# IWRL6432 register map
File version: 1.0
CPU: CM4 1.0, other endian, MPU, FPU, 3 interrupt priority bits
Registers are 32-bit, read-write, reset 0x0 unless marked. A register's access mark holds for its fields unless they carry their own. Offsets are from the block's base; [hi:lo] are bit positions; {n}, {i} and the like mark numbered series; 'fields as' and 'values as' point back to an identical list.

## TPCC_B (part 1 of 2) — TPCC
Base 0x55080000
Same registers: TPCC_A 0x56000000
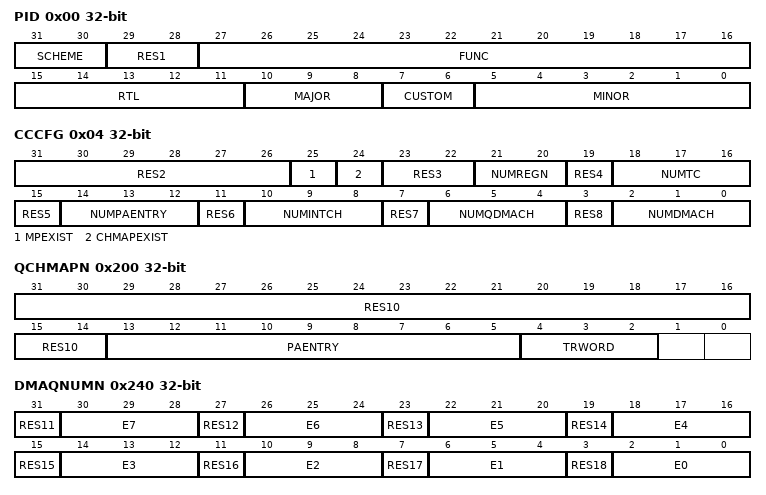
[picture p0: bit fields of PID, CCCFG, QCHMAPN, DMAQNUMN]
0x00 PID — Peripheral ID Register
  [31:30] SCHEME — [31:30] PID Scheme: Used to distinguish between old ID scheme and current. Spare bit to encode future schemes EDMA uses 'new scheme' indicated with value of 0x1.
  [29:28] RES1 — [29:28] RESERVE FIELD
  [27:16] FUNC — [27:16] Function indicates a software compatible module family.
  [15:11] RTL — [15:11] RTL Version
  [10:8] MAJOR — [10:8] Major Revision
  [7:6] CUSTOM — [7:6] Custom revision field: Not used on this version of EDMA.
  [5:0] MINOR — [5:0] Minor Revision
0x04 CCCFG — CC Configuration Register
  [31:26] RES2 — [31:26] RESERVE FIELD
  [25] MPEXIST — [25:25] Memory Protection Existence MPEXIST = 0 : No memory protection. MPEXIST = 1 : Memory Protection logic included.
  [24] CHMAPEXIST — [24:24] Channel Mapping Existence CHMAPEXIST = 0 : No Channel mapping. CHMAPEXIST = 1 : Channel mapping logic included.
  [23:22] RES3 — [23:22] RESERVE FIELD
  [21:20] NUMREGN — [21:20] Number of MP and Shadow regions
  [35-4n] RES{n} (n=4..8) — [{35-4n}:{35-4n}] RESERVE FIELD
  [18:16] NUMTC — [18:16] Number of Queues/Number of TCs
  [14:12] NUMPAENTRY — [14:12] Number of PaRAM entries
  [10:8] NUMINTCH — [10:8] Number of Interrupt Channels
  [6:4] NUMQDMACH — [6:4] Number of QDMA Channels
  [2:0] NUMDMACH — [2:0] Number of DMA Channels
0x200 QCHMAPN — QDMA Channel N Mapping Register
  [31:14] RES10 — [31:14] RESERVE FIELD
  [13:5] PAENTRY — [13:5] PaRAM Entry number for QDMA Channel N.
  [4:2] TRWORD — [4:2] TRWORD points to the specific trigger word of the PaRAM Entry defined by PAENTRY. A write to the trigger word results in a QDMA Event being recognized.
0x240 DMAQNUMN — DMA Queue Number Register n Contains the Event queue number to be used for the corresponding DMA Channel.
  [75-4n] RES{n} (n=11..18) — [{75-4n}:{75-4n}] RESERVE FIELD
  [4n+2:4n] E{n} (n=0..7) — [{4n+2}:{4n}] DMA Queue Number for event #{n}
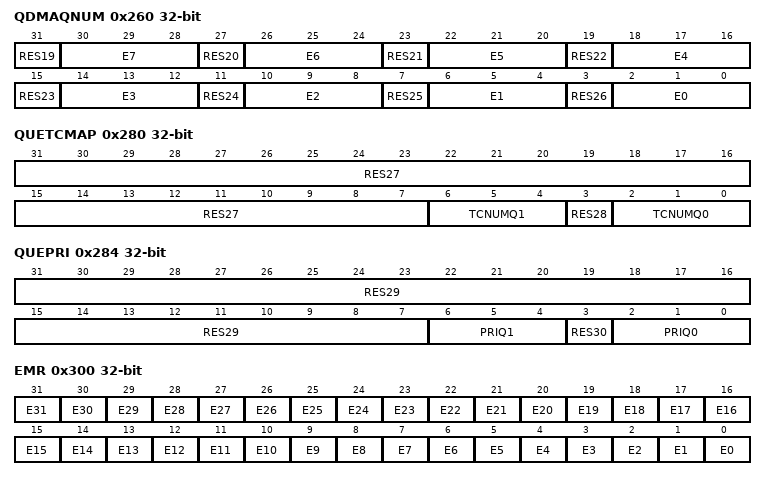
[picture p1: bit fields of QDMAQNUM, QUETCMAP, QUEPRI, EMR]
0x260 QDMAQNUM — QDMA Queue Number Register Contains the Event queue number to be used for the corresponding QDMA Channel.
  [107-4n] RES{n} (n=19..26) — [{107-4n}:{107-4n}] RESERVE FIELD
  [4n+2:4n] E{n} (n=0..7) — [{4n+2}:{4n}] QDMA Queue Number for event #{n}
0x280 QUETCMAP — Queue to TC Mapping
  [31:7] RES27 — [31:7] RESERVE FIELD
  [6:4] TCNUMQ1 — [6:4] TC Number for Queue N: Defines the TC number that Event Queue N TRs are written to.
  [3] RES28 — [3:3] RESERVE FIELD
  [2:0] TCNUMQ0 — [2:0] TC Number for Queue N: Defines the TC number that Event Queue N TRs are written to.
0x284 QUEPRI — Queue Priority
  [31:7] RES29 — [31:7] RESERVE FIELD
  [6:4] PRIQ1 — [6:4] Priority Level for Queue 1 Dictates the priority level used for the OPTIONS field programmation for Qn TRs. Sets the priority used for TC read and write commands.
  [3] RES30 — [3:3] RESERVE FIELD
  [2:0] PRIQ0 — [2:0] Priority Level for Queue 0 Dictates the priority level used for the OPTIONS field programmation for Qn TRs. Sets the priority used for TC read and write commands.
0x300 EMR — Event Missed Register: The Event Missed register is set if 2 events are received without the first event being cleared or if a Null TR is serviced. Chained events (CER) Set Events (ESR) and normal events (ER) are treated individually. If any bit in the EMR register is set (and all errors (including QEMR/CCERR) were previously clear) then an error will be signaled with TPCC error interrupt.
  [n] E{n} (n=0..31) — [{n}:{n}] Event Missed #{n}
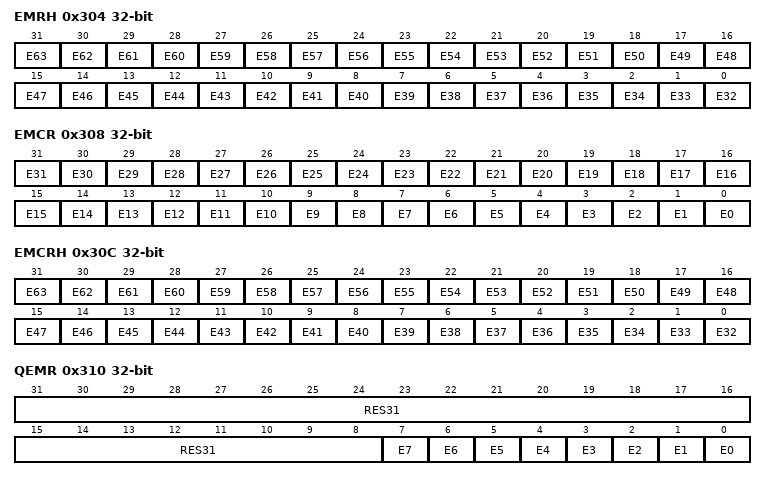
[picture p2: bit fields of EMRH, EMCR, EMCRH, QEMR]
0x304 EMRH — Event Missed Register (High Part): The Event Missed register is set if 2 events are received without the first event being cleared or if a Null TR is serviced. Chained events (CER) Set Events (ESR) and normal events (ER) are treated individually. If any bit in the EMR register is set (and all errors (including QEMR/CCERR) were previously clear) then an error will be signaled with TPCC error interrupt.
  [n-32] E{n} (n=32..63) — [{n-32}:{n-32}] Event Missed #{n}
0x308 EMCR — Event Missed Clear Register: CPU write of '1' to the EMCR.En bit causes the EMR.En bit to be cleared. CPU write of '0' has no effect.. All error bits must be cleared before additional error interrupts will be asserted by CC.
  [n] E{n} (n=0..31) — [{n}:{n}] Event Missed Clear #{n}
0x30C EMCRH — Event Missed Clear Register (High Part): CPU write of '1' to the EMCR.En bit causes the EMR.En bit to be cleared. CPU write of '0' has no effect.. All error bits must be cleared before additional error interrupts will be asserted by CC.
  [n-32] E{n} (n=32..63) — [{n-32}:{n-32}] Event Missed Clear #{n}
0x310 QEMR — QDMA Event Missed Register: The QDMA Event Missed register is set if 2 QDMA events are detected without the first event being cleared or if a Null TR is serviced.. If any bit in the QEMR register is set (and all errors (including EMR/CCERR) were previously clear) then an error will be signaled with TPCC error interrupt.
  [31:8] RES31 — [31:8] RESERVE FIELD
  [n] E{n} (n=0..7) — [{n}:{n}] Event Missed #{n}
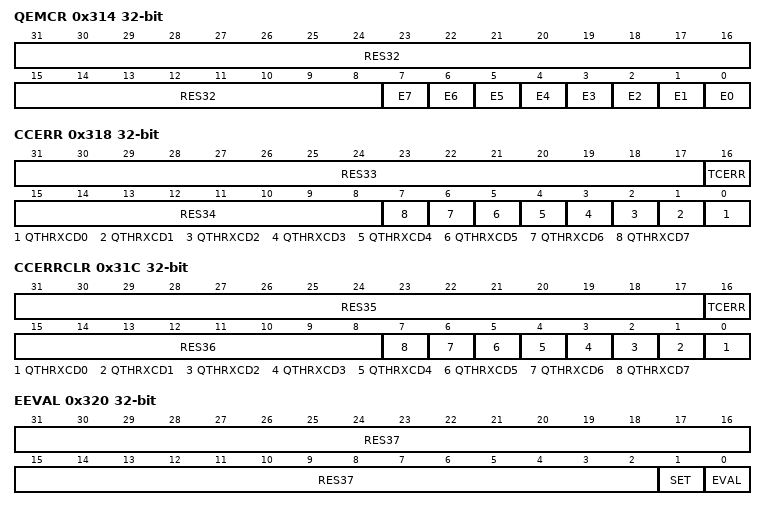
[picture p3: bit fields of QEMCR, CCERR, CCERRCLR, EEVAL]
0x314 QEMCR — QDMA Event Missed Clear Register: CPU write of '1' to the QEMCR.En bit causes the QEMR.En bit to be cleared. CPU write of '0' has no effect.. All error bits must be cleared before additional error interrupts will be asserted by CC.
  [31:8] RES32 — [31:8] RESERVE FIELD
  [n] E{n} (n=0..7) — [{n}:{n}] Event Missed Clear #{n}
0x318 CCERR — CC Error Register
  [31:17] RES33 — [31:17] RESERVE FIELD
  [16] TCERR — [16:16] Transfer Completion Code Error: TCCERR = 0 : Total number of allowed TCCs outstanding has not been reached. TCCERR = 1 : Total number of allowed TCCs has been reached. TCCERR can be cleared by writing a '1' to corresponding bit in CCERRCLR register. If any bit in the CCERR register is set (and all errors were previously clear) then an error will be signaled with TPCC error interrupt.
  [15:8] RES34 — [15:8] RESERVE FIELD
  [n] QTHRXCD{n} (n=0..7) — [{n}:{n}] Queue Threshold Error for Q{n}: QTHRXCD{n} = 0 : Watermark/threshold has not been exceeded. QTHRXCD{n} = 1 : Watermark/threshold has been exceeded. CCERR.QTHRXCD{n} can be cleared by writing a '1' to corresponding bit in CCERRCLR register. If any bit in the CCERR register is set (and all errors (including EMR/QEMR) were previously clear) then an error will be signaled with the TPCC error interrupt.
0x31C CCERRCLR — CC Error Clear Register
  [31:17] RES35 — [31:17] RESERVE FIELD
  [16] TCERR — [16:16] Clear Error for CCERR.TCERR: Write of '1' clears the value of CCERR bit N. Writes of '0' have no affect.
  [15:8] RES36 — [15:8] RESERVE FIELD
  [n] QTHRXCD{n} (n=0..7) — [{n}:{n}] Clear error for CCERR.QTHRXCD{n}: Write of '1' clears the values of QSTAT{n}.WM QSTAT{n}.THRXCD CCERR.QTHRXCD{n} Writes of '0' have no affect.
0x320 EEVAL — Error Eval Register
  [31:2] RES37 — [31:2] RESERVE FIELD
  [1] SET — [1:1] Error Interrupt Set: CPU write of '1' to the SET bit causes the TPCC error interrupt to be pulsed regardless of state of EMR/EMRH QEMR or CCERR. CPU write of '0' has no effect.
  [0] EVAL — [0:0] Error Interrupt Evaluate: CPU write of '1' to the EVAL bit causes the TPCC error interrupt to be pulsed if any errors have not been cleared in the EMR/EMRH QEMR or CCERR registers. CPU write of '0' has no effect.
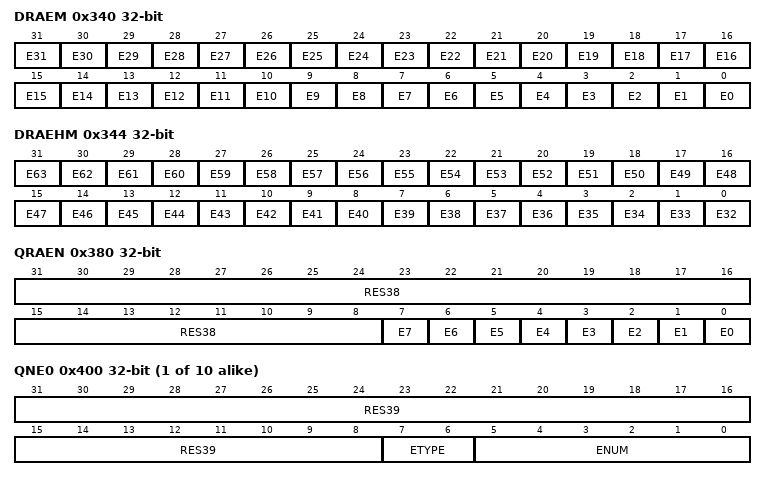
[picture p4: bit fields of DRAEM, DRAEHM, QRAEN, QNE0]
0x340 DRAEM — DMA Region Access enable for bit N in Region M: En = 0 : Accesses via Region M address space to Bit N in any DMA Channel Register are not allowed. Reads will return 'b0 on Bit N and writes will not modify the state of bit N. Enabled interrupt bits for bit N do not contribute to the generation of the TPCC region M interrupt. En = 1 : Accesses via Region M address space to Bit N in any DMA Channel Register are allowed. Reads will return the value from Bit N and writes will modify the state of bit N. Enabled interrupt bits for bit N do contribute to the generation of the TPCC region M interrupt.
  [n] E{n} (n=0..31) — [{n}:{n}] DMA Region Access enable for Region M bit #{n}
0x344 DRAEHM — DMA Region Access enable for bit N in Region M: En = 0 : Accesses via Region M address space to Bit N in any DMA Channel Register are not allowed. Reads will return 'b0 on Bit N and writes will not modify the state of bit N. Enabled interrupt bits for bit N do not contribute to the generation of the TPCC region M interrupt. En = 1 : Accesses via Region M address space to Bit N in any DMA Channel Register are allowed. Reads will return the value from Bit N and writes will modify the state of bit N. Enabled interrupt bits for bit N do contribute to the generation of the TPCC region M interrupt. En = 0 : Accesses via Region M address space to Bit N in any DMA Channel Register are not allowed. Reads will return 'b0 on Bit N and writes will not modify the state of bit N. Enabled interrupt bits for bit N do not contribute to the generation of the TPCC region M interrupt. En = 1 : Accesses via Region M address space to Bit N in any DMA Channel Register are allowed. Reads will return the value from Bit N and writes will modify the state of bit N. Enabled interrupt bits for bit N do contribute to the generation of the TPCC region M interrupt.
  [n-32] E{n} (n=32..63) — [{n-32}:{n-32}] DMA Region Access enable for Region M bit #{n}
0x380 QRAEN — QDMA Region Access enable for bit N in Region M: En = 0 : Accesses via Region M address space to Bit N in any QDMA Channel Register are not allowed. Reads will return 'b0 on Bit N and writes will not modify the state of bit N. Enabled interrupt bits for bit N do not contribute to the generation of the TPCC region M interrupt. En = 1 : Accesses via Region M address space to Bit N in any QDMA Channel Register are allowed. Reads will return the value from Bit N and writes will modify the state of bit N. Enabled interrupt bits for bit N do contribute to the generation of the TPCC region n interrupt.
  [31:8] RES38 — [31:8] RESERVE FIELD
  [n] E{n} (n=0..7) — [{n}:{n}] QDMA Region Access enable for Region M bit #{n}
{0x400+4i} QNE{i} (i=0..9) — Event Queue Entry Diagram for Queue n - Entry {i}
  [31:8] RES{i+39} — [31:8] RESERVE FIELD
  [7:6] ETYPE — [7:6] Event Type: Specifies the specific Event Type for the given entry in the Event Queue.
  [5:0] ENUM — [5:0] Event Number: Specifies the specific Event Number for the given entry in the Event Queue. For DMA Channel events (ER/ESR/CER) ENUM will range between 0 and NUM_DMACH (up to 63). For QDMA Channel events (QER) ENUM will range between 0 and NUM_QDMACH (up to 7).
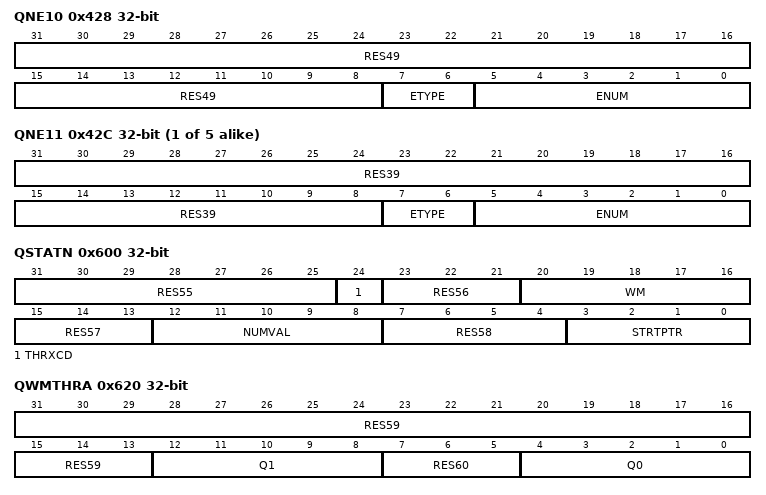
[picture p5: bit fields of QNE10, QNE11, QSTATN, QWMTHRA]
0x428 QNE10 — Event Queue Entry Diagram for Queue n - Entry 0
  [31:8] RES49 — [31:8] RESERVE FIELD
  [7:6] ETYPE — [7:6] Event Type: Specifies the specific Event Type for the given entry in the Event Queue.
  [5:0] ENUM — [5:0] Event Number: Specifies the specific Event Number for the given entry in the Event Queue. For DMA Channel events (ER/ESR/CER) ENUM will range between 0 and NUM_DMACH (up to 63). For QDMA Channel events (QER) ENUM will range between 0 and NUM_QDMACH (up to 7).
{0x400+4i} QNE{i} (i=11..15) — Event Queue Entry Diagram for Queue n - Entry {i}
  fields as QNE0
0x600 QSTATN — QSTATn Register Set
  [31:25] RES55 — [31:25] RESERVE FIELD
  [24] THRXCD — [24:24] Threshold Exceeded: THRXCD = 0 : Threshold specified by QWMTHR(A B).Qn has not been exceeded. THRXCD = 1 : Threshold specified by QWMTHR(A B).Qn has been exceeded. QSTATn.THRXCD is cleared via CCERR.WMCLRn bit.
  [23:21] RES56 — [23:21] RESERVE FIELD
  [20:16] WM — [20:16] Watermark for Maximum Queue Usage: Watermark tracks the most entries that have been in QueueN since reset or since the last time that the watermark (WM) was cleared. QSTATn.WM is cleared via CCERR.WMCLRn bit. Legal values = 0x0 (empty) to 0x10 (full)
  [15:13] RES57 — [15:13] RESERVE FIELD
  [12:8] NUMVAL — [12:8] Number of Valid Entries in QueueN: Represents the total number of entries residing in the Queue Manager FIFO at a given instant. Always enabled. Legal values = 0x0 (empty) to 0x10 (full)
  [7:4] RES58 — [7:4] RESERVE FIELD
  [3:0] STRTPTR — [3:0] Start Pointer: Represents the offset to the head entry of QueueN in units of entries. Always enabled. Legal values = 0x0 (0th entry) to 0xF (15th entry)
0x620 QWMTHRA — Queue Threshold A for Q[3:0]: CCERR.QTHRXCDn and QSTATn.THRXCD error bit is set when the number of Events in QueueN at an instant in time (visible via QSTATn.NUMVAL) equals or exceeds the value specified by QWMTHRA.Qn. Legal values = 0x0 (ever used?) to 0x10 (ever full?) A value of 0x11 disables threshold errors.
  [31:13] RES59 — [31:13] RESERVE FIELD
  [12:8] Q1 — [12:8] Queue Threshold for Q1 value
  [7:5] RES60 — [7:5] RESERVE FIELD
  [4:0] Q0 — [4:0] Queue Threshold for Q0 value
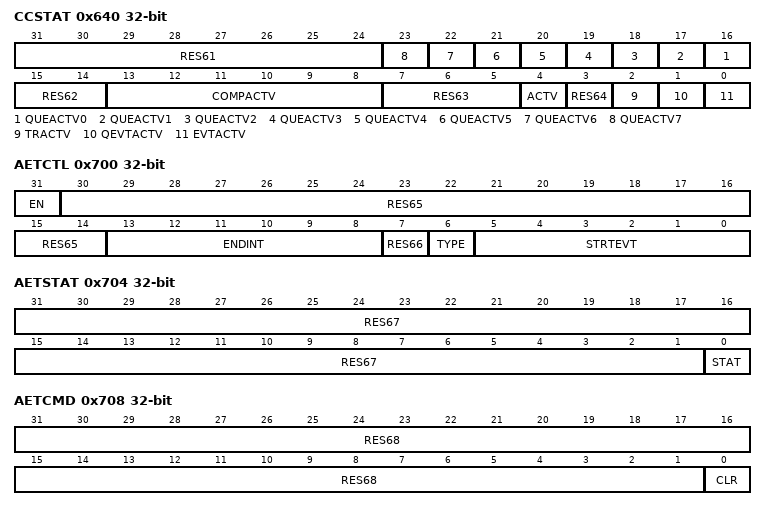
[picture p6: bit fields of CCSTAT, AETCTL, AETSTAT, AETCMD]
0x640 CCSTAT — CC Status Register
  [31:24] RES61 — [31:24] RESERVE FIELD
  [n+16] QUEACTV{n} (n=0..7) — [{n+16}:{n+16}] Queue {n} Active QUEACTV{n} = 0 : No Evts are queued in Q{n}. QUEACTV{n} = 1 : At least one TR is queued in Q{n}.
  [15:14] RES62 — [15:14] RESERVE FIELD
  [13:8] COMPACTV — [13:8] Completion Request Active: Counter that tracks the total number of completion requests submitted to the TC. The counter increments when a TR is submitted with TCINTEN or TCCHEN set to '1'. The counter decrements for every valid completion code received from any of the external TCs. The CC will not service new TRs if COMPACTV count is already at the limit. COMPACTV = 0 : No completion requests outstanding. COMPACTV = 1: Total of '1' completion request outstanding. ... COMPACTV = 63 : Total of 63 completion requests are outstanding. No additional TRs will be submitted until count is less than 63.
  [7:5] RES63 — [7:5] RESERVE FIELD
  [4] ACTV — [4:4] Channel Controller Active: Channel Controller Active is a logical-OR of each of the ACTV signals. The ACTV bit must remain high through the life of a TR. ACTV = 0 : Channel is idle. ACTV = 1 : Channel is busy.
  [3] RES64 — [3:3] RESERVE FIELD
  [2] TRACTV — [2:2] Transfer Request Active: TRACTV = 0 : Transfer Request processing/submission logic is inactive. TRACTV = 1 : Transfer Request processing/submission logic is active.
  [1] QEVTACTV — [1:1] QDMA Event Active: QEVTACTV = 0 : No enabled QDMA Events are active within the CC. QEVTACTV = 1 : At least one enabled DMA Event (ER & EER ESR CER) is active within the CC.
  [0] EVTACTV — [0:0] DMA Event Active: EVTACTV = 0 : No enabled DMA Events are active within the CC. EVTACTV = 1 : At least one enabled DMA Event (ER & EER ESR CER) is active within the CC.
0x700 AETCTL — Advanced Event Trigger Control
  [31] EN — [31:31] AET Enable: EN = 0 : AET event generation is disabled. EN = 1 : AET event generation is enabled.
  [30:14] RES65 — [30:14] RESERVE FIELD
  [13:8] ENDINT — [13:8] AET End Interrupt: Dictates the completion interrupt number that will force the tpcc_aet signal to be deasserted (low)
  [7] RES66 — [7:7] RESERVE FIELD
  [6] TYPE — [6:6] AET Event Type: TYPE = 0 : Event specified by STARTEVT applies to DMA Events (set by ER ESR or CER) TYPE = 1 : Event specified by STARTEVT applies to QDMA Events
  [5:0] STRTEVT — [5:0] AET Start Event: Dictates the Event Number that will force the tpcc_aet signal to be asserted (high)
0x704 AETSTAT — Advanced Event Trigger Stat
  [31:1] RES67 — [31:1] RESERVE FIELD
  [0] STAT — [0:0] AET Status: AETSTAT = 0 : tpcc_aet is currently low. AETSTAT = 1 : tpcc_aet is currently high.
0x708 AETCMD — AET Command
  [31:1] RES68 — [31:1] RESERVE FIELD
  [0] CLR — [0:0] AET Clear command: CPU write of '1' to the CLR bit causes the tpcc_aet output signal and AETSTAT.STAT register to be cleared. CPU write of '0' has no effect..
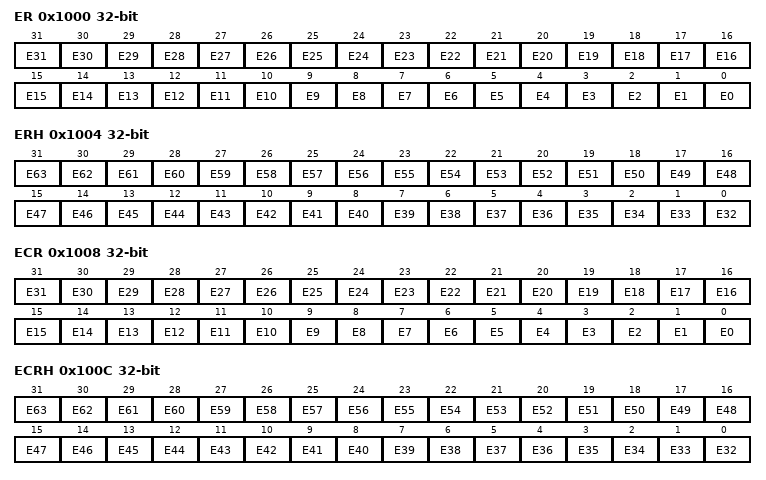
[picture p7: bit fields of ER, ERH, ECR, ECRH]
0x1000 ER — Event Register: If ER.En bit is set and the EER.En bit is also set then the corresponding DMA channel is prioritized vs. other pending DMA events for submission to the TC. ER.En bit is set when the input event #n transitions from inactive (low) to active (high) regardless of the state of EER.En bit. ER.En bit is cleared when the corresponding event is prioritized and serviced. If the ER.En bit is already set and a new inactive to active transition is detected on the input event #n input AND the corresponding bit in the EER register is set then the corresponding bit in the Event Missed Register is set. Event N can be cleared via sw by writing a '1' to the ECR pseudo-register.
  [n] E{n} (n=0..31) — [{n}:{n}] Event #{n}
0x1004 ERH — Event Register (High Part): If ERH.En bit is set and the EERH.En bit is also set then the corresponding DMA channel is prioritized vs. other pending DMA events for submission to the TC. ERH.En bit is set when the input event #n transitions from inactive (low) to active (high) regardless of the state of EERH.En bit. ER.En bit is cleared when the corresponding event is prioritized and serviced. If the ERH.En bit is already set and a new inactive to active transition is detected on the input event #n input AND the corresponding bit in the EERH register is set then the corresponding bit in the Event Missed Register is set. Event N can be cleared via sw by writing a '1' to the ECRH pseudo-register.
  [n-32] E{n} (n=32..63) — [{n-32}:{n-32}] Event #{n}
0x1008 ECR — Event Clear Register: CPU write of '1' to the ECR.En bit causes the ER.En bit to be cleared. CPU write of '0' has no effect.
  [n] E{n} (n=0..31) — [{n}:{n}] Event #{n}
0x100C ECRH — Event Clear Register (High Part): CPU write of '1' to the ECRH.En bit causes the ERH.En bit to be cleared. CPU write of '0' has no effect.
  [n-32] E{n} (n=32..63) — [{n-32}:{n-32}] Event #{n}
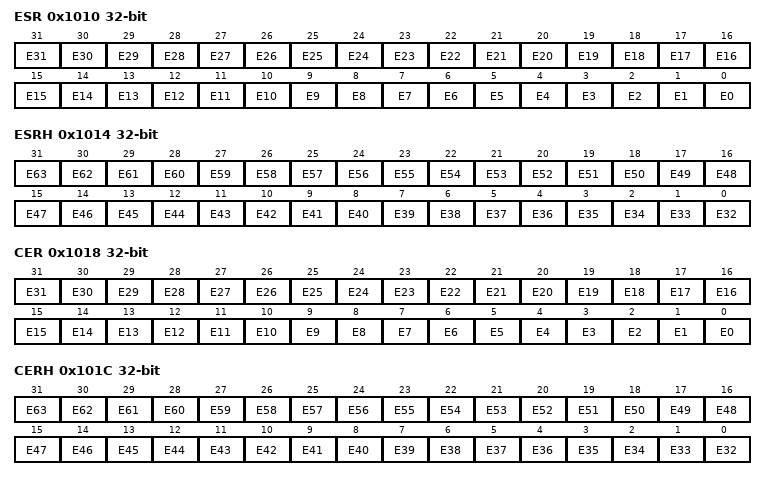
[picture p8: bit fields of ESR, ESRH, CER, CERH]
0x1010 ESR — Event Set Register: CPU write of '1' to the ESR.En bit causes the ER.En bit to be set. CPU write of '0' has no effect.
  [n] E{n} (n=0..31) — [{n}:{n}] Event #{n}
0x1014 ESRH — Event Set Register (High Part) CPU write of '1' to the ESRH.En bit causes the ERH.En bit to be set. CPU write of '0' has no effect.
  [n-32] E{n} (n=32..63) — [{n-32}:{n-32}] Event #{n}
0x1018 CER — Chained Event Register: If CER.En bit is set (regardless of state of EER.En) then the corresponding DMA channel is prioritized vs. other pending DMA events for submission to the TC. CER.En bit is set when a chaining completion code is returned from one of the 3PTCs via the completion interface or is generated internally via Early Completion path. CER.En bit is cleared when the corresponding event is prioritized and serviced. If the CER.En bit is already set and the corresponding chaining completion code is returned from the TC then the corresponding bit in the Event Missed Register is set. CER.En cannot be set or cleared via software.
  [n] E{n} (n=0..31) — [{n}:{n}] Event #{n}
0x101C CERH — Chained Event Register (High Part): If CERH.En bit is set (regardless of state of EERH.En) then the corresponding DMA channel is prioritized vs. other pending DMA events for submission to the TC. CERH.En bit is set when a chaining completion code is returned from one of the 3PTCs via the completion interface or is generated internally via Early Completion path. CERH.En bit is cleared when the corresponding event is prioritized and serviced. If the CERH.En bit is already set and the corresponding chaining completion code is returned from the TC then the corresponding bit in the Event Missed Register is set. CERH.En cannot be set or cleared via software.
  [n-32] E{n} (n=32..63) — [{n-32}:{n-32}] Event #{n}
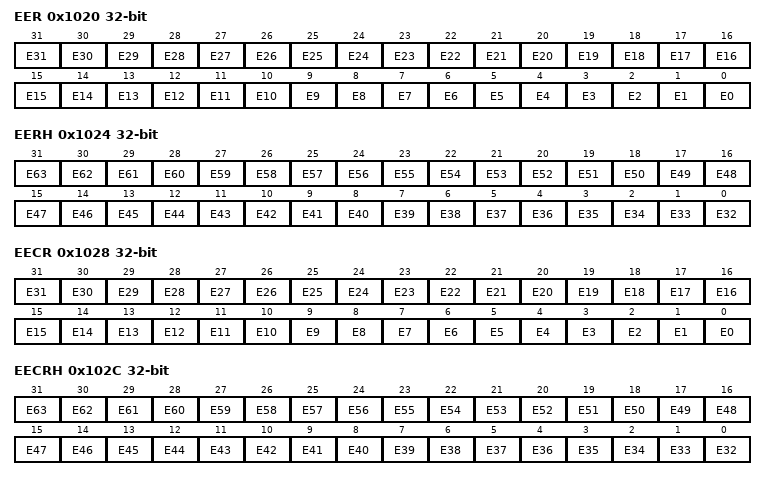
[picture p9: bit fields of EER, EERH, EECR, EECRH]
0x1020 EER — Event Enable Register: Enables DMA transfers for ER.En pending events. ER.En is set based on externally asserted events (via tpcc_eventN_pi). This register has no effect on Chained Event Register (CER) or Event Set Register (ESR). Note that if a bit is set in ER.En while EER.En is disabled no action is taken. If EER.En is enabled at a later point (and ER.En has not been cleared via SW) then the event will be recognized as a valid 'TR Sync' EER.En is not directly writeable. Events can be enabled via writes to EESR and can be disabled via writes to EECR register. EER.En = 0: ER.En is not enabled to trigger DMA transfers. EER.En = 1: ER.En is enabled to trigger DMA transfers.
  [n] E{n} (n=0..31) — [{n}:{n}] Event #{n}
0x1024 EERH — Event Enable Register (High Part): Enables DMA transfers for ERH.En pending events. ERH.En is set based on externally asserted events (via tpcc_eventN_pi). This register has no effect on Chained Event Register (CERH) or Event Set Register (ESRH). Note that if a bit is set in ERH.En while EERH.En is disabled no action is taken. If EERH.En is enabled at a later point (and ERH.En has not been cleared via SW) then the event will be recognized as a valid 'TR Sync' EERH.En is not directly writeable. Events can be enabled via writes to EESRH and can be disabled via writes to EECRH register. EERH.En = 0: ER.En is not enabled to trigger DMA transfers. EERH.En = 1: ER.En is enabled to trigger DMA transfers.
  [n-32] E{n} (n=32..63) — [{n-32}:{n-32}] Event #{n}
0x1028 EECR — Event Enable Clear Register: CPU write of '1' to the EECR.En bit causes the EER.En bit to be cleared. CPU write of '0' has no effect..
  [n] E{n} (n=0..31) — [{n}:{n}] Event #{n}
0x102C EECRH — Event Enable Clear Register (High Part): CPU write of '1' to the EECRH.En bit causes the EERH.En bit to be cleared. CPU write of '0' has no effect..
  [n-32] E{n} (n=32..63) — [{n-32}:{n-32}] Event #{n}
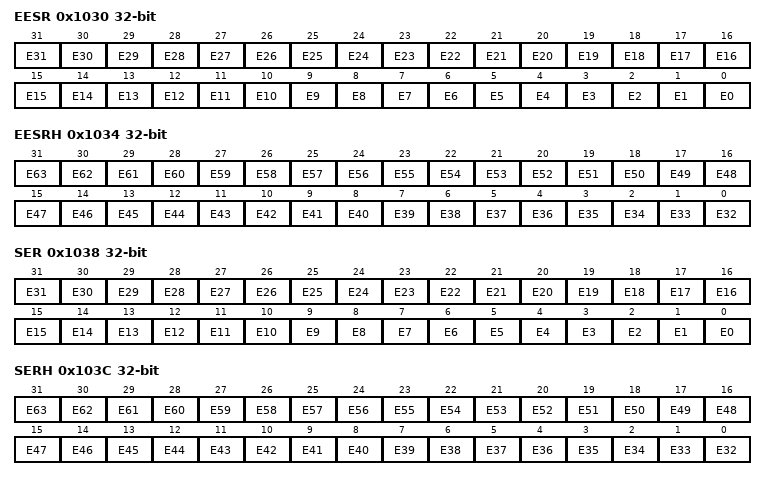
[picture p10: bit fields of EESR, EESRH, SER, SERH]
0x1030 EESR — Event Enable Set Register: CPU write of '1' to the EESR.En bit causes the EER.En bit to be set. CPU write of '0' has no effect..
  [n] E{n} (n=0..31) — [{n}:{n}] Event #{n}
0x1034 EESRH — Event Enable Set Register (High Part): CPU write of '1' to the EESRH.En bit causes the EERH.En bit to be set. CPU write of '0' has no effect..
  [n-32] E{n} (n=32..63) — [{n-32}:{n-32}] Event #{n}
0x1038 SER — Secondary Event Register: The secondary event register is used along with the Event Register (ER) to provide information on the state of an Event. En = 0 : Event is not currently in the Event Queue. En = 1 : Event is currently stored in Event Queue. Event arbiter will not prioritize additional events.
  [n] E{n} (n=0..31) — [{n}:{n}] Event #{n}
0x103C SERH — Secondary Event Register (High Part): The secondary event register is used along with the Event Register (ERH) to provide information on the state of an Event. En = 0 : Event is not currently in the Event Queue. En = 1 : Event is currently stored in Event Queue. Event arbiter will not prioritize additional events.
  [n-32] E{n} (n=32..63) — [{n-32}:{n-32}] Event #{n}
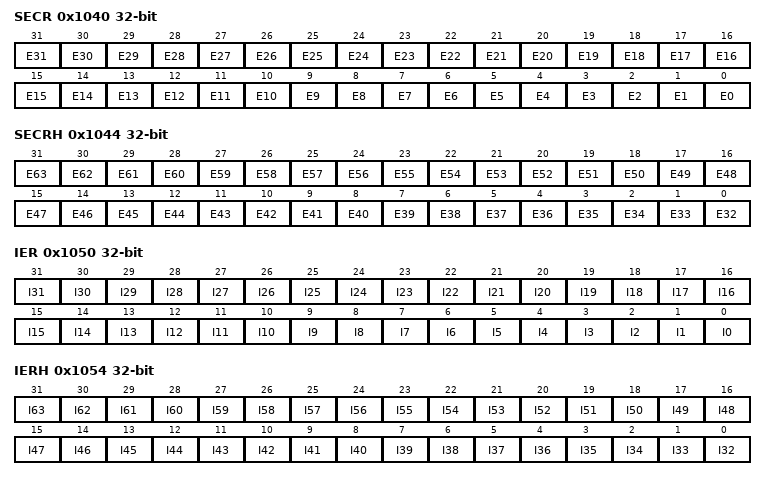
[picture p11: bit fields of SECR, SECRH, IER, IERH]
0x1040 SECR — Secondary Event Clear Register: The secondary event clear register is used to clear the status of the SER registers. CPU write of '1' to the SECR.En bit clears the SER register. CPU write of '0' has no effect.
  [n] E{n} (n=0..31) — [{n}:{n}] Event #{n}
0x1044 SECRH — Secondary Event Clear Register (High Part): The secondary event clear register is used to clear the status of the SERH registers. CPU write of '1' to the SECRH.En bit clears the SERH register. CPU write of '0' has no effect.
  [n-32] E{n} (n=32..63) — [{n-32}:{n-32}] Event #{n}
0x1050 IER — Int Enable Register: IER.In is not directly writeable. Interrupts can be enabled via writes to IESR and can be disabled via writes to IECR register. IER.In = 0: IPR.In is NOT enabled for interrupts. IER.In = 1: IPR.In IS enabled for interrupts.
  [n] I{n} (n=0..31) — [{n}:{n}] Interrupt associated with TCC #{n}
0x1054 IERH — Int Enable Register (High Part): IERH.In is not directly writeable. Interrupts can be enabled via writes to IESRH and can be disabled via writes to IECRH register. IERH.In = 0: IPRH.In is NOT enabled for interrupts. IERH.In = 1: IPRH.In IS enabled for interrupts.
  [n-32] I{n} (n=32..63) — [{n-32}:{n-32}] Interrupt associated with TCC #{n}
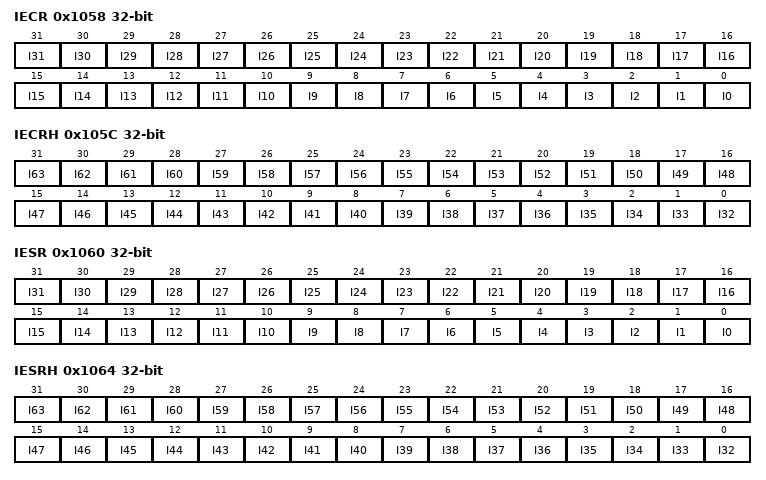
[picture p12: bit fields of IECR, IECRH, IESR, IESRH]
0x1058 IECR — Int Enable Clear Register: CPU write of '1' to the IECR.In bit causes the IER.In bit to be cleared. CPU write of '0' has no effect..
  [n] I{n} (n=0..31) — [{n}:{n}] Interrupt associated with TCC #{n}
0x105C IECRH — Int Enable Clear Register (High Part): CPU write of '1' to the IECRH.In bit causes the IERH.In bit to be cleared. CPU write of '0' has no effect..
  fields as IERH
0x1060 IESR — Int Enable Set Register: CPU write of '1' to the IESR.In bit causes the IESR.In bit to be set. CPU write of '0' has no effect..
  [n] I{n} (n=0..31) — [{n}:{n}] Interrupt associated with TCC #{n}
0x1064 IESRH — Int Enable Set Register (High Part): CPU write of '1' to the IESRH.In bit causes the IESRH.In bit to be set. CPU write of '0' has no effect..
  fields as IERH
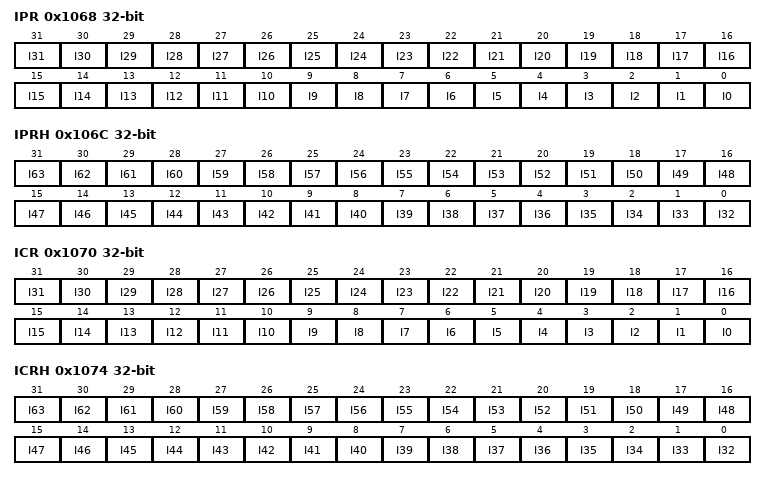
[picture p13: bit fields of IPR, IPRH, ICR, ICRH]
0x1068 IPR — Interrupt Pending Register: IPR.In bit is set when a interrupt completion code with TCC of N is detected. IPR.In bit is cleared via software by writing a '1' to ICR.In bit.
  [n] I{n} (n=0..31) — [{n}:{n}] Interrupt associated with TCC #{n}
0x106C IPRH — Interrupt Pending Register (High Part): IPRH.In bit is set when a interrupt completion code with TCC of N is detected. IPRH.In bit is cleared via software by writing a '1' to ICRH.In bit.
  fields as IERH
0x1070 ICR — Interrupt Clear Register: CPU write of '1' to the ICR.In bit causes the IPR.In bit to be cleared. CPU write of '0' has no effect. All IPR.In bits must be cleared before additional interrupts will be asserted by CC.
  [n] I{n} (n=0..31) — [{n}:{n}] Interrupt associated with TCC #{n}
0x1074 ICRH — Interrupt Clear Register (High Part): CPU write of '1' to the ICRH.In bit causes the IPRH.In bit to be cleared. CPU write of '0' has no effect. All IPRH.In bits must be cleared before additional interrupts will be asserted by CC.
  fields as IERH
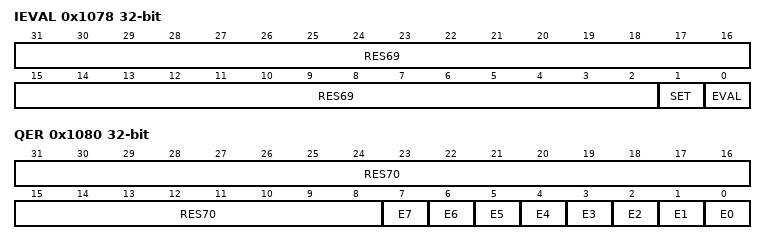
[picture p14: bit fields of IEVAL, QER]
0x1078 IEVAL — Interrupt Eval Register
  [31:2] RES69 — [31:2] RESERVE FIELD
  [1] SET — [1:1] Interrupt Set: CPU write of '1' to the SETn bit causes the tpcc_intN output signal to be pulsed egardless of state of interrupts enable (IERn) and status (IPRn). CPU write of '0' has no effect.
  [0] EVAL — [0:0] Interrupt Evaluate: CPU write of '1' to the EVALn bit causes the tpcc_intN output signal to be pulsed if any enabled interrupts (IERn) are still pending (IPRn). CPU write of '0' has no effect..
0x1080 QER — QDMA Event Register: If QER.En bit is set then the corresponding QDMA channel is prioritized vs. other qdma events for submission to the TC. QER.En bit is set when a vbus write byte matches the address defined in the QCHMAPn register. QER.En bit is cleared when the corresponding event is prioritized and serviced. QER.En is also cleared when user writes a '1' to the QSECR.En bit. If the QER.En bit is already set and a new QDMA event is detected due to user write to QDMA trigger location and QEER register is set then the corresponding bit in the QDMA Event Missed Register is set.
  [31:8] RES70 — [31:8] RESERVE FIELD
  [n] E{n} (n=0..7) — [{n}:{n}] Event #{n}
